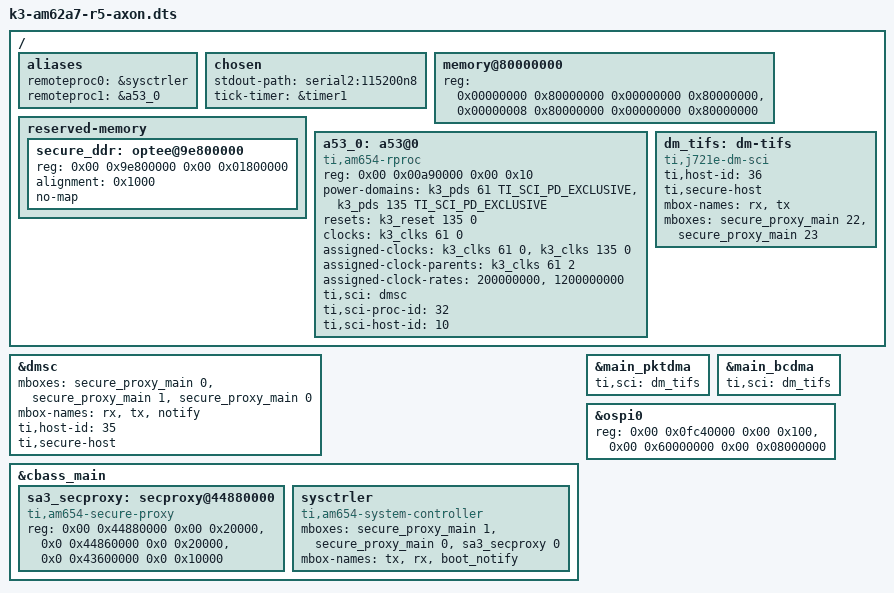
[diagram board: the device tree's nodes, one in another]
// SPDX-License-Identifier: GPL-2.0
/*
 * Copyright (C) 2022 Texas Instruments Incorporated - https://www.ti.com/
 * Copyright 2023 TechNexion Ltd.
 * Author: Ray Chang <ray.chang@technexion.com>
 */

#include "k3-am62a7-axon.dts"
#include "k3-am62a-ddr-1866mhz-32bit.dtsi"
#include "k3-am62a-ddr.dtsi"

#include "k3-am62a7-axon-u-boot.dtsi"

/ {
	aliases {
		remoteproc0 = &sysctrler;
		remoteproc1 = &a53_0;
	};

	chosen {
		stdout-path = "serial2:115200n8";
		tick-timer = &timer1;
	};

	memory@80000000 {
		device_type = "memory";
		/* 4G RAM */
		reg = <0x00000000 0x80000000 0x00000000 0x80000000>,
		      <0x00000008 0x80000000 0x00000000 0x80000000>;
		u-boot,dm-spl;
	};

	reserved-memory {
		#address-cells = <2>;
		#size-cells = <2>;
		ranges;

		secure_ddr: optee@9e800000 {
			reg = <0x00 0x9e800000 0x00 0x01800000>; /* for OP-TEE */
			alignment = <0x1000>;
			no-map;
		};
	};

	a53_0: a53@0 {
		compatible = "ti,am654-rproc";
		reg = <0x00 0x00a90000 0x00 0x10>;
		power-domains = <&k3_pds 61 TI_SCI_PD_EXCLUSIVE>,
				<&k3_pds 135 TI_SCI_PD_EXCLUSIVE>;
		resets = <&k3_reset 135 0>;
		clocks = <&k3_clks 61 0>;
		assigned-clocks = <&k3_clks 61 0>, <&k3_clks 135 0>;
		assigned-clock-parents = <&k3_clks 61 2>;
		assigned-clock-rates = <200000000>, <1200000000>;
		ti,sci = <&dmsc>;
		ti,sci-proc-id = <32>;
		ti,sci-host-id = <10>;
		u-boot,dm-spl;
	};

	dm_tifs: dm-tifs {
		compatible = "ti,j721e-dm-sci";
		ti,host-id = <36>;
		ti,secure-host;
		mbox-names = "rx", "tx";
		mboxes= <&secure_proxy_main 22>,
			<&secure_proxy_main 23>;
		u-boot,dm-spl;
	};
};

&dmsc {
	mboxes= <&secure_proxy_main 0>,
		<&secure_proxy_main 1>,
		<&secure_proxy_main 0>;
	mbox-names = "rx", "tx", "notify";
	ti,host-id = <35>;
	ti,secure-host;
};

&cbass_main {
	sa3_secproxy: secproxy@44880000 {
		compatible = "ti,am654-secure-proxy";
		#mbox-cells = <1>;
		reg = <0x00 0x44880000 0x00 0x20000>,
		      <0x0 0x44860000 0x0 0x20000>,
		      <0x0 0x43600000 0x0 0x10000>;
		reg-names = "rt", "scfg", "target_data";
		u-boot,dm-spl;
	};

	sysctrler: sysctrler {
		compatible = "ti,am654-system-controller";
		mboxes= <&secure_proxy_main 1>,
			<&secure_proxy_main 0>,
			<&sa3_secproxy 0>;
		mbox-names = "tx", "rx", "boot_notify";
		u-boot,dm-spl;
	};
};

&main_pktdma {
	ti,sci = <&dm_tifs>;
};

&main_bcdma {
	ti,sci = <&dm_tifs>;
};

&ospi0 {
	reg = <0x00 0x0fc40000 0x00 0x100>,
	      <0x00 0x60000000 0x00 0x08000000>;
};
